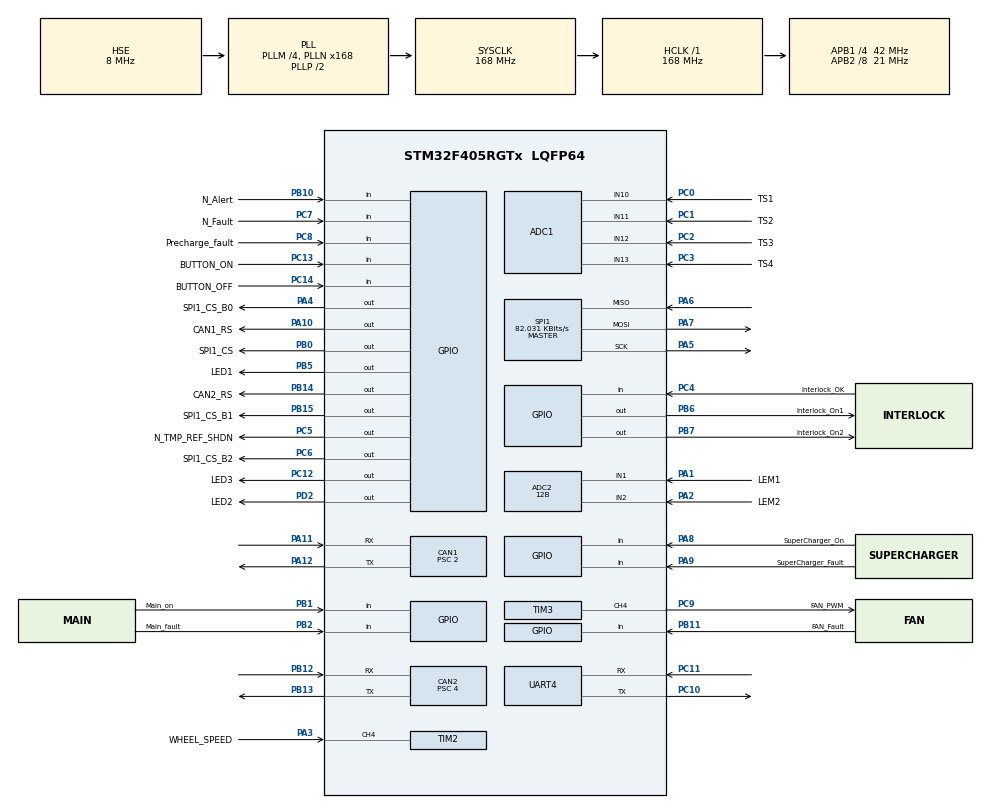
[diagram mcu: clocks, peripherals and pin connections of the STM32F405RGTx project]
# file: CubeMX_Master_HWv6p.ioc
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ADC1.Channel-15\#ChannelRegularConversion=ADC_CHANNEL_10
ADC1.Channel-16\#ChannelRegularConversion=ADC_CHANNEL_11
ADC1.Channel-17\#ChannelRegularConversion=ADC_CHANNEL_12
ADC1.Channel-18\#ChannelRegularConversion=ADC_CHANNEL_13
ADC1.ClockPrescaler=ADC_CLOCK_SYNC_PCLK_DIV2
ADC1.DMAContinuousRequests=ENABLE
ADC1.EOCSelection=ADC_EOC_SEQ_CONV
ADC1.NbrOfConversion=4
ADC1.NbrOfConversionFlag=1
ADC1.Rank-15\#ChannelRegularConversion=1
ADC1.Rank-16\#ChannelRegularConversion=2
ADC1.Rank-17\#ChannelRegularConversion=3
ADC1.Rank-18\#ChannelRegularConversion=4
ADC1.SamplingTime-15\#ChannelRegularConversion=ADC_SAMPLETIME_28CYCLES
ADC1.SamplingTime-16\#ChannelRegularConversion=ADC_SAMPLETIME_28CYCLES
ADC1.SamplingTime-17\#ChannelRegularConversion=ADC_SAMPLETIME_28CYCLES
ADC1.SamplingTime-18\#ChannelRegularConversion=ADC_SAMPLETIME_28CYCLES
ADC1.ScanConvMode=ENABLE
ADC1.master=1
ADC2.Channel-0\#ChannelRegularConversion=ADC_CHANNEL_1
ADC2.Channel-1\#ChannelRegularConversion=ADC_CHANNEL_2
ADC2.ClockPrescaler=ADC_CLOCK_SYNC_PCLK_DIV2
ADC2.ContinuousConvMode=DISABLE
ADC2.DMAContinuousRequests=ENABLE
ADC2.DataAlign=ADC_DATAALIGN_RIGHT
ADC2.DiscontinuousConvMode=DISABLE
ADC2.EOCSelection=ADC_EOC_SEQ_CONV
ADC2.EnableAnalogWatchDog=false
ADC2.ExternalTrigConv=ADC_SOFTWARE_START
ADC2.ExternalTrigConvEdge=ADC_EXTERNALTRIGCONVEDGE_NONE
ADC2.InjNumberOfConversion=0
ADC2.NbrOfConversion=2
ADC2.NbrOfConversionFlag=1
ADC2.Rank-0\#ChannelRegularConversion=1
ADC2.Rank-1\#ChannelRegularConversion=2
ADC2.Resolution=ADC_RESOLUTION_12B
ADC2.SamplingTime-0\#ChannelRegularConversion=ADC_SAMPLETIME_28CYCLES
ADC2.SamplingTime-1\#ChannelRegularConversion=ADC_SAMPLETIME_28CYCLES
ADC2.ScanConvMode=ENABLE
CAN1.BS1=CAN_BS1_12TQ
CAN1.BS2=CAN_BS2_8TQ
CAN1.CalculateTimeBit=1000
CAN1.CalculateTimeQuantum=47.61904761904762
CAN1.Prescaler=2
CAN2.BS1=CAN_BS1_12TQ
CAN2.BS2=CAN_BS2_8TQ
CAN2.CalculateTimeBit=2000
CAN2.CalculateTimeQuantum=95.23809523809524
CAN2.Prescaler=4
Dma.ADC1.1.Direction=DMA_PERIPH_TO_MEMORY
Dma.ADC1.1.FIFOMode=DMA_FIFOMODE_DISABLE
Dma.ADC1.1.Instance=DMA2_Stream0
Dma.ADC1.1.MemDataAlignment=DMA_MDATAALIGN_HALFWORD
Dma.ADC1.1.MemInc=DMA_MINC_ENABLE
Dma.ADC1.1.Mode=DMA_CIRCULAR
Dma.ADC1.1.PeriphDataAlignment=DMA_PDATAALIGN_HALFWORD
Dma.ADC1.1.PeriphInc=DMA_PINC_DISABLE
Dma.ADC1.1.Priority=DMA_PRIORITY_LOW
Dma.ADC2.0.Direction=DMA_PERIPH_TO_MEMORY
Dma.ADC2.0.FIFOMode=DMA_FIFOMODE_DISABLE
Dma.ADC2.0.Instance=DMA2_Stream2
Dma.ADC2.0.MemDataAlignment=DMA_MDATAALIGN_HALFWORD
Dma.ADC2.0.MemInc=DMA_MINC_ENABLE
Dma.ADC2.0.Mode=DMA_CIRCULAR
Dma.ADC2.0.PeriphDataAlignment=DMA_PDATAALIGN_HALFWORD
Dma.ADC2.0.PeriphInc=DMA_PINC_DISABLE
Dma.ADC2.0.Priority=DMA_PRIORITY_LOW
Dma.Request0=ADC2
Dma.Request1=ADC1
Mcu.Family=STM32F4
Mcu.Name=STM32F405RGTx
Mcu.Package=LQFP64
Mcu.UserConstants=BMS_MASTER_VERSION,6;TIM_6_FREQUENCY,4000;TIM_7_FREQUENCY,20;ADC1_NUM_CHANNELS,4;ADC2_NUM_CHANNELS,2;ADC_RANGE,4095
NVIC.CAN1_RX0_IRQn=true\:0\:0\:false\:false\:true
NVIC.CAN1_RX1_IRQn=true\:0\:0\:false\:false\:true
NVIC.CAN1_SCE_IRQn=true\:0\:0\:false\:false\:true
NVIC.CAN1_TX_IRQn=true\:0\:0\:false\:false\:true
NVIC.CAN2_RX0_IRQn=true\:0\:0\:false\:false\:true
NVIC.CAN2_RX1_IRQn=true\:0\:0\:false\:false\:true
NVIC.CAN2_SCE_IRQn=true\:0\:0\:false\:false\:true
NVIC.CAN2_TX_IRQn=true\:0\:0\:false\:false\:true
NVIC.DMA2_Stream0_IRQn=true\:0\:0\:false\:false\:true
NVIC.DMA2_Stream2_IRQn=true\:0\:0\:false\:false\:true
NVIC.PriorityGroup=NVIC_PRIORITYGROUP_4
NVIC.SPI1_IRQn=true\:0\:0\:false\:false\:true
NVIC.TIM2_IRQn=true\:0\:0\:false\:false\:true
NVIC.TIM3_IRQn=true\:0\:0\:false\:false\:true
NVIC.TIM6_DAC_IRQn=true\:0\:0\:false\:false\:true
NVIC.TIM7_IRQn=true\:0\:0\:false\:false\:true
PA1.GPIO_Label=LEM1
PA1.Signal=ADCx_IN1
PA10.GPIO_Label=CAN1_RS
PA10.Signal=GPIO_Output
PA11.Mode=Master
PA11.Signal=CAN1_RX
PA12.Mode=Master
PA12.Signal=CAN1_TX
PA13.Mode=JTAG_5_pins
PA13.Signal=SYS_JTMS-SWDIO
PA14.Mode=JTAG_5_pins
PA14.Signal=SYS_JTCK-SWCLK
PA15.Mode=JTAG_5_pins
PA15.Signal=SYS_JTDI
PA2.GPIO_Label=LEM2
PA2.Signal=ADCx_IN2
PA3.GPIO_Label=WHEEL_SPEED
PA3.Signal=S_TIM2_CH4
PA4.GPIO_Label=SPI1_CS_B0
PA4.GPIO_ModeDefaultOutputPP=GPIO_MODE_OUTPUT_OD
PA4.Signal=GPIO_Output
PA5.Mode=Full_Duplex_Master
PA5.Signal=SPI1_SCK
PA6.Mode=Full_Duplex_Master
PA6.Signal=SPI1_MISO
PA7.Mode=Full_Duplex_Master
PA7.Signal=SPI1_MOSI
PA8.GPIO_Label=SuperCharger_On
PA8.Signal=GPIO_Input
PA9.GPIO_Label=SuperCharger_Fault
PA9.Signal=GPIO_Input
PB0.GPIO_Label=SPI1_CS
PB0.GPIO_ModeDefaultOutputPP=GPIO_MODE_OUTPUT_OD
PB0.GPIO_Speed=GPIO_SPEED_FREQ_HIGH
PB0.Signal=GPIO_Output
PB1.GPIO_Label=Main_on
PB1.Signal=GPIO_Input
PB10.GPIO_Label=N_Alert
PB10.Signal=GPIO_Input
PB11.GPIO_Label=FAN_Fault
PB11.Signal=GPIO_Input
PB12.Mode=Slave
PB12.Signal=CAN2_RX
PB13.Mode=Slave
PB13.Signal=CAN2_TX
PB14.GPIO_Label=CAN2_RS
PB14.Signal=GPIO_Output
PB15.GPIO_Label=SPI1_CS_B1
PB15.GPIO_ModeDefaultOutputPP=GPIO_MODE_OUTPUT_OD
PB15.Signal=GPIO_Output
PB2.GPIO_Label=Main_fault
PB2.Signal=GPIO_Input
PB3.Mode=JTAG_5_pins
PB3.Signal=SYS_JTDO-SWO
PB4.Mode=JTAG_5_pins
PB4.Signal=SYS_JTRST
PB5.GPIO_Label=LED1
PB5.Signal=GPIO_Output
PB6.GPIO_Label=Interlock_On1
PB6.Signal=GPIO_Output
PB7.GPIO_Label=Interlock_On2
PB7.Signal=GPIO_Output
PC0.GPIO_Label=TS1
PC0.Signal=ADCx_IN10
PC1.GPIO_Label=TS2
PC1.Signal=ADCx_IN11
PC10.Mode=Asynchronous
PC10.Signal=UART4_TX
PC11.Mode=Asynchronous
PC11.Signal=UART4_RX
PC12.GPIO_Label=LED3
PC12.Signal=GPIO_Output
PC13-ANTI_TAMP.GPIO_Label=BUTTON_ON
PC13-ANTI_TAMP.GPIO_PuPd=GPIO_PULLDOWN
PC13-ANTI_TAMP.Signal=GPIO_Input
PC14-OSC32_IN.GPIO_Label=BUTTON_OFF
PC14-OSC32_IN.GPIO_PuPd=GPIO_PULLDOWN
PC14-OSC32_IN.Signal=GPIO_Input
PC2.GPIO_Label=TS3
PC2.Signal=ADCx_IN12
PC3.GPIO_Label=TS4
PC3.Signal=ADCx_IN13
PC4.GPIO_Label=Interlock_OK
PC4.GPIO_PuPd=GPIO_PULLDOWN
PC4.Signal=GPIO_Input
PC5.GPIO_Label=N_TMP_REF_SHDN
PC5.Signal=GPIO_Output
PC6.GPIO_Label=SPI1_CS_B2
PC6.GPIO_ModeDefaultOutputPP=GPIO_MODE_OUTPUT_OD
PC6.Signal=GPIO_Output
PC7.GPIO_Label=N_Fault
PC7.Signal=GPIO_Input
PC8.GPIO_Label=Precharge_fault
PC8.Signal=GPIO_Input
PC9.GPIO_Label=FAN_PWM
PC9.Signal=S_TIM3_CH4
PD2.GPIO_Label=LED2
PD2.Signal=GPIO_Output
PH0-OSC_IN.Mode=HSE-External-Oscillator
PH0-OSC_IN.Signal=RCC_OSC_IN
PH1-OSC_OUT.Mode=HSE-External-Oscillator
PH1-OSC_OUT.Signal=RCC_OSC_OUT
ProjectManager.HeapSize=0x200
ProjectManager.StackSize=0x400
ProjectManager.TargetToolchain=Other Toolchains (GPDSC)
RCC.48MHZClocksFreq_Value=84000000
RCC.AHBFreq_Value=168000000
RCC.APB1CLKDivider=RCC_HCLK_DIV4
RCC.APB1Freq_Value=42000000
RCC.APB1TimFreq_Value=84000000
RCC.APB2CLKDivider=RCC_HCLK_DIV8
RCC.APB2Freq_Value=21000000
RCC.APB2TimFreq_Value=42000000
RCC.CortexFreq_Value=168000000
RCC.HCLKFreq_Value=168000000
RCC.HSE_VALUE=8000000
RCC.HSI_VALUE=16000000
RCC.LSE_VALUE=32768
RCC.PLLM=4
RCC.PLLN=168
RCC.PLLSourceVirtual=RCC_PLLSOURCE_HSE
RCC.SYSCLKFreq_VALUE=168000000
RCC.SYSCLKSource=RCC_SYSCLKSOURCE_PLLCLK
RCC.VCOOutputFreq_Value=336000000
SH.ADCx_IN1.0=ADC2_IN1,IN1
SH.ADCx_IN10.0=ADC1_IN10,IN10
SH.ADCx_IN11.0=ADC1_IN11,IN11
SH.ADCx_IN12.0=ADC1_IN12,IN12
SH.ADCx_IN13.0=ADC1_IN13,IN13
SH.ADCx_IN2.0=ADC2_IN2,IN2
SH.S_TIM2_CH4.0=TIM2_CH4,Input_Capture4_from_TI4
SH.S_TIM3_CH4.0=TIM3_CH4,PWM Generation4 CH4
SPI1.BaudRatePrescaler=SPI_BAUDRATEPRESCALER_256
SPI1.CLKPhase=SPI_PHASE_2EDGE
SPI1.CRCCalculation=SPI_CRCCALCULATION_ENABLE
SPI1.CRCPolynomial=X2+X1+X0
SPI1.CalculateBaudRate=82.031 KBits/s
SPI1.Direction=SPI_DIRECTION_2LINES
SPI1.Mode=SPI_MODE_MASTER
SPI1.VirtualType=VM_MASTER
TIM2.Channel-Input_Capture4_from_TI4=TIM_CHANNEL_4
TIM2.ICFilter_CH4=7
TIM2.Period=3600000000
TIM2.Prescaler=839
TIM3.Channel-PWM\ Generation4\ CH4=TIM_CHANNEL_4
TIM6.Period=250
TIM6.Prescaler=83
TIM7.Period=500
TIM7.Prescaler=8399
UART4.VirtualMode=Asynchronous
VP_TIM3_VS_ClockSourceINT.Mode=Internal
VP_TIM6_VS_ClockSourceINT.Mode=Enable_Timer
VP_TIM7_VS_ClockSourceINT.Mode=Enable_Timer
board=CubeMX_Master_HWv6p

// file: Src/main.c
/**
  ******************************************************************************
  * File Name          : main.c
  * Description        : Main program body
  ******************************************************************************
  *
  * COPYRIGHT(c) 2017 STMicroelectronics
  *
  * Redistribution and use in source and binary forms, with or without modification,
  * are permitted provided that the following conditions are met:
  *   1. Redistributions of source code must retain the above copyright notice,
  *      this list of conditions and the following disclaimer.
  *   2. Redistributions in binary form must reproduce the above copyright notice,
  *      this list of conditions and the following disclaimer in the documentation
  *      and/or other materials provided with the distribution.
  *   3. Neither the name of STMicroelectronics nor the names of its contributors
  *      may be used to endorse or promote products derived from this software
  *      without specific prior written permission.
  *
  * THIS SOFTWARE IS PROVIDED BY THE COPYRIGHT HOLDERS AND CONTRIBUTORS "AS IS"
  * AND ANY EXPRESS OR IMPLIED WARRANTIES, INCLUDING, BUT NOT LIMITED TO, THE
  * IMPLIED WARRANTIES OF MERCHANTABILITY AND FITNESS FOR A PARTICULAR PURPOSE ARE
  * DISCLAIMED. IN NO EVENT SHALL THE COPYRIGHT HOLDER OR CONTRIBUTORS BE LIABLE
  * FOR ANY DIRECT, INDIRECT, INCIDENTAL, SPECIAL, EXEMPLARY, OR CONSEQUENTIAL
  * DAMAGES (INCLUDING, BUT NOT LIMITED TO, PROCUREMENT OF SUBSTITUTE GOODS OR
  * SERVICES; LOSS OF USE, DATA, OR PROFITS; OR BUSINESS INTERRUPTION) HOWEVER
  * CAUSED AND ON ANY THEORY OF LIABILITY, WHETHER IN CONTRACT, STRICT LIABILITY,
  * OR TORT (INCLUDING NEGLIGENCE OR OTHERWISE) ARISING IN ANY WAY OUT OF THE USE
  * OF THIS SOFTWARE, EVEN IF ADVISED OF THE POSSIBILITY OF SUCH DAMAGE.
  *
  ******************************************************************************
  */
#include "main.h"
#include "stm32f4xx_hal.h"

/* USER CODE BEGIN Includes */
#include "../../Src/core/userProgram.h"
/* USER CODE END Includes */

ADC_HandleTypeDef hadc1;
ADC_HandleTypeDef hadc2;
DMA_HandleTypeDef hdma_adc1;
DMA_HandleTypeDef hdma_adc2;

CAN_HandleTypeDef hcan1;
CAN_HandleTypeDef hcan2;

SPI_HandleTypeDef hspi1;

TIM_HandleTypeDef htim2;
TIM_HandleTypeDef htim3;
TIM_HandleTypeDef htim6;
TIM_HandleTypeDef htim7;

UART_HandleTypeDef huart4;

/* USER CODE BEGIN PV */
/* Private variables ---------------------------------------------------------*/

/* USER CODE END PV */

void SystemClock_Config(void);
void Error_Handler(void);
static void MX_GPIO_Init(void);
static void MX_DMA_Init(void);
static void MX_ADC2_Init(void);
static void MX_CAN1_Init(void);
static void MX_CAN2_Init(void);
static void MX_SPI1_Init(void);
static void MX_TIM3_Init(void);
static void MX_UART4_Init(void);
static void MX_TIM6_Init(void);
static void MX_TIM7_Init(void);
static void MX_ADC1_Init(void);
static void MX_TIM2_Init(void);

void HAL_TIM_MspPostInit(TIM_HandleTypeDef *htim);

/* USER CODE BEGIN PFP */
/* Private function prototypes -----------------------------------------------*/

/* USER CODE END PFP */

int main(void)
{

  /* MCU Configuration----------------------------------------------------------*/

  /* Reset of all peripherals, Initializes the Flash interface and the Systick. */
  HAL_Init();

  /* Configure the system clock */
  SystemClock_Config();

  /* Initialize all configured peripherals */
  MX_GPIO_Init();
  MX_DMA_Init();
  MX_ADC2_Init();
  MX_CAN1_Init();
  MX_CAN2_Init();
  MX_SPI1_Init();
  MX_TIM3_Init();
  MX_UART4_Init();
  MX_TIM6_Init();
  MX_TIM7_Init();
  MX_ADC1_Init();
  MX_TIM2_Init();

  /* USER CODE BEGIN 2 */
  userInit();
  /* USER CODE END 2 */

  /* Infinite loop */
  while (1)
  {

  /* USER CODE BEGIN 3 */
    userLoop();
  }
  /* USER CODE END 3 */

}

/** System Clock Configuration
*/
void SystemClock_Config(void)
{

  RCC_OscInitTypeDef RCC_OscInitStruct;
  RCC_ClkInitTypeDef RCC_ClkInitStruct;

    /**Configure the main internal regulator output voltage
    */
  __HAL_RCC_PWR_CLK_ENABLE();

  __HAL_PWR_VOLTAGESCALING_CONFIG(PWR_REGULATOR_VOLTAGE_SCALE1);

    /**Initializes the CPU, AHB and APB busses clocks
    */
  RCC_OscInitStruct.OscillatorType = RCC_OSCILLATORTYPE_HSE;
  RCC_OscInitStruct.HSEState = RCC_HSE_ON;
  RCC_OscInitStruct.PLL.PLLState = RCC_PLL_ON;
  RCC_OscInitStruct.PLL.PLLSource = RCC_PLLSOURCE_HSE;
  RCC_OscInitStruct.PLL.PLLM = 4;
  RCC_OscInitStruct.PLL.PLLN = 168;
  RCC_OscInitStruct.PLL.PLLP = RCC_PLLP_DIV2;
  RCC_OscInitStruct.PLL.PLLQ = 4;
  if (HAL_RCC_OscConfig(&RCC_OscInitStruct) != HAL_OK)
  {
    Error_Handler();
  }

    /**Initializes the CPU, AHB and APB busses clocks
    */
  RCC_ClkInitStruct.ClockType = RCC_CLOCKTYPE_HCLK|RCC_CLOCKTYPE_SYSCLK
                              |RCC_CLOCKTYPE_PCLK1|RCC_CLOCKTYPE_PCLK2;
  RCC_ClkInitStruct.SYSCLKSource = RCC_SYSCLKSOURCE_PLLCLK;
  RCC_ClkInitStruct.AHBCLKDivider = RCC_SYSCLK_DIV1;
  RCC_ClkInitStruct.APB1CLKDivider = RCC_HCLK_DIV4;
  RCC_ClkInitStruct.APB2CLKDivider = RCC_HCLK_DIV8;

  if (HAL_RCC_ClockConfig(&RCC_ClkInitStruct, FLASH_LATENCY_5) != HAL_OK)
  {
    Error_Handler();
  }

    /**Configure the Systick interrupt time
    */
  HAL_SYSTICK_Config(HAL_RCC_GetHCLKFreq()/1000);

    /**Configure the Systick
    */
  HAL_SYSTICK_CLKSourceConfig(SYSTICK_CLKSOURCE_HCLK);

  /* SysTick_IRQn interrupt configuration */
  HAL_NVIC_SetPriority(SysTick_IRQn, 0, 0);
}

/* ADC1 init function */
static void MX_ADC1_Init(void)
{

  ADC_ChannelConfTypeDef sConfig;

    /**Configure the global features of the ADC (Clock, Resolution, Data Alignment and number of conversion)
    */
  hadc1.Instance = ADC1;
  hadc1.Init.ClockPrescaler = ADC_CLOCK_SYNC_PCLK_DIV2;
  hadc1.Init.Resolution = ADC_RESOLUTION_12B;
  hadc1.Init.ScanConvMode = ENABLE;
  hadc1.Init.ContinuousConvMode = DISABLE;
  hadc1.Init.DiscontinuousConvMode = DISABLE;
  hadc1.Init.ExternalTrigConvEdge = ADC_EXTERNALTRIGCONVEDGE_NONE;
  hadc1.Init.ExternalTrigConv = ADC_SOFTWARE_START;
  hadc1.Init.DataAlign = ADC_DATAALIGN_RIGHT;
  hadc1.Init.NbrOfConversion = 4;
  hadc1.Init.DMAContinuousRequests = ENABLE;
  hadc1.Init.EOCSelection = ADC_EOC_SEQ_CONV;
  if (HAL_ADC_Init(&hadc1) != HAL_OK)
  {
    Error_Handler();
  }

    /**Configure for the selected ADC regular channel its corresponding rank in the sequencer and its sample time.
    */
  sConfig.Channel = ADC_CHANNEL_10;
  sConfig.Rank = 1;
  sConfig.SamplingTime = ADC_SAMPLETIME_28CYCLES;
  if (HAL_ADC_ConfigChannel(&hadc1, &sConfig) != HAL_OK)
  {
    Error_Handler();
  }

    /**Configure for the selected ADC regular channel its corresponding rank in the sequencer and its sample time.
    */
  sConfig.Channel = ADC_CHANNEL_11;
  sConfig.Rank = 2;
  if (HAL_ADC_ConfigChannel(&hadc1, &sConfig) != HAL_OK)
  {
    Error_Handler();
  }

    /**Configure for the selected ADC regular channel its corresponding rank in the sequencer and its sample time.
    */
  sConfig.Channel = ADC_CHANNEL_12;
  sConfig.Rank = 3;
  if (HAL_ADC_ConfigChannel(&hadc1, &sConfig) != HAL_OK)
  {
    Error_Handler();
  }

    /**Configure for the selected ADC regular channel its corresponding rank in the sequencer and its sample time.
    */
  sConfig.Channel = ADC_CHANNEL_13;
  sConfig.Rank = 4;
  if (HAL_ADC_ConfigChannel(&hadc1, &sConfig) != HAL_OK)
  {
    Error_Handler();
  }

}

/* ADC2 init function */
static void MX_ADC2_Init(void)
{

  ADC_ChannelConfTypeDef sConfig;

    /**Configure the global features of the ADC (Clock, Resolution, Data Alignment and number of conversion)
    */
  hadc2.Instance = ADC2;
  hadc2.Init.ClockPrescaler = ADC_CLOCK_SYNC_PCLK_DIV2;
  hadc2.Init.Resolution = ADC_RESOLUTION_12B;
  hadc2.Init.ScanConvMode = ENABLE;
  hadc2.Init.ContinuousConvMode = DISABLE;
  hadc2.Init.DiscontinuousConvMode = DISABLE;
  hadc2.Init.ExternalTrigConvEdge = ADC_EXTERNALTRIGCONVEDGE_NONE;
  hadc2.Init.ExternalTrigConv = ADC_SOFTWARE_START;
  hadc2.Init.DataAlign = ADC_DATAALIGN_RIGHT;
  hadc2.Init.NbrOfConversion = 2;
  hadc2.Init.DMAContinuousRequests = ENABLE;
  hadc2.Init.EOCSelection = ADC_EOC_SEQ_CONV;
  if (HAL_ADC_Init(&hadc2) != HAL_OK)
  {
    Error_Handler();
  }

    /**Configure for the selected ADC regular channel its corresponding rank in the sequencer and its sample time.
    */
  sConfig.Channel = ADC_CHANNEL_1;
  sConfig.Rank = 1;
  sConfig.SamplingTime = ADC_SAMPLETIME_28CYCLES;
  if (HAL_ADC_ConfigChannel(&hadc2, &sConfig) != HAL_OK)
  {
    Error_Handler();
  }

    /**Configure for the selected ADC regular channel its corresponding rank in the sequencer and its sample time.
    */
  sConfig.Channel = ADC_CHANNEL_2;
  sConfig.Rank = 2;
  if (HAL_ADC_ConfigChannel(&hadc2, &sConfig) != HAL_OK)
  {
    Error_Handler();
  }

}

/* CAN1 init function */
static void MX_CAN1_Init(void)
{

  hcan1.Instance = CAN1;
  hcan1.Init.Prescaler = 2;
  hcan1.Init.Mode = CAN_MODE_NORMAL;
  hcan1.Init.SJW = CAN_SJW_1TQ;
  hcan1.Init.BS1 = CAN_BS1_12TQ;
  hcan1.Init.BS2 = CAN_BS2_8TQ;
  hcan1.Init.TTCM = DISABLE;
  hcan1.Init.ABOM = DISABLE;
  hcan1.Init.AWUM = DISABLE;
  hcan1.Init.NART = DISABLE;
  hcan1.Init.RFLM = DISABLE;
  hcan1.Init.TXFP = DISABLE;
  if (HAL_CAN_Init(&hcan1) != HAL_OK)
  {
    Error_Handler();
  }

}

/* CAN2 init function */
static void MX_CAN2_Init(void)
{

  hcan2.Instance = CAN2;
  hcan2.Init.Prescaler = 4;
  hcan2.Init.Mode = CAN_MODE_NORMAL;
  hcan2.Init.SJW = CAN_SJW_1TQ;
  hcan2.Init.BS1 = CAN_BS1_12TQ;
  hcan2.Init.BS2 = CAN_BS2_8TQ;
  hcan2.Init.TTCM = DISABLE;
  hcan2.Init.ABOM = DISABLE;
  hcan2.Init.AWUM = DISABLE;
  hcan2.Init.NART = DISABLE;
  hcan2.Init.RFLM = DISABLE;
  hcan2.Init.TXFP = DISABLE;
  if (HAL_CAN_Init(&hcan2) != HAL_OK)
  {
    Error_Handler();
  }

}

/* SPI1 init function */
static void MX_SPI1_Init(void)
{

  hspi1.Instance = SPI1;
  hspi1.Init.Mode = SPI_MODE_MASTER;
  hspi1.Init.Direction = SPI_DIRECTION_2LINES;
  hspi1.Init.DataSize = SPI_DATASIZE_8BIT;
  hspi1.Init.CLKPolarity = SPI_POLARITY_LOW;
  hspi1.Init.CLKPhase = SPI_PHASE_2EDGE;
  hspi1.Init.NSS = SPI_NSS_SOFT;
  hspi1.Init.BaudRatePrescaler = SPI_BAUDRATEPRESCALER_256;
  hspi1.Init.FirstBit = SPI_FIRSTBIT_MSB;
  hspi1.Init.TIMode = SPI_TIMODE_DISABLE;
  hspi1.Init.CRCCalculation = SPI_CRCCALCULATION_ENABLE;
  hspi1.Init.CRCPolynomial = 7;
  if (HAL_SPI_Init(&hspi1) != HAL_OK)
  {
    Error_Handler();
  }

}

/* TIM2 init function */
static void MX_TIM2_Init(void)
{

  TIM_MasterConfigTypeDef sMasterConfig;
  TIM_IC_InitTypeDef sConfigIC;

  htim2.Instance = TIM2;
  htim2.Init.Prescaler = 839;
  htim2.Init.CounterMode = TIM_COUNTERMODE_UP;
  htim2.Init.Period = 3600000000;
  htim2.Init.ClockDivision = TIM_CLOCKDIVISION_DIV1;
  if (HAL_TIM_IC_Init(&htim2) != HAL_OK)
  {
    Error_Handler();
  }

  sMasterConfig.MasterOutputTrigger = TIM_TRGO_RESET;
  sMasterConfig.MasterSlaveMode = TIM_MASTERSLAVEMODE_DISABLE;
  if (HAL_TIMEx_MasterConfigSynchronization(&htim2, &sMasterConfig) != HAL_OK)
  {
    Error_Handler();
  }

  sConfigIC.ICPolarity = TIM_INPUTCHANNELPOLARITY_RISING;
  sConfigIC.ICSelection = TIM_ICSELECTION_DIRECTTI;
  sConfigIC.ICPrescaler = TIM_ICPSC_DIV1;
  sConfigIC.ICFilter = 7;
  if (HAL_TIM_IC_ConfigChannel(&htim2, &sConfigIC, TIM_CHANNEL_4) != HAL_OK)
  {
    Error_Handler();
  }

}

/* TIM3 init function */
static void MX_TIM3_Init(void)
{

  TIM_ClockConfigTypeDef sClockSourceConfig;
  TIM_MasterConfigTypeDef sMasterConfig;
  TIM_OC_InitTypeDef sConfigOC;

  htim3.Instance = TIM3;
  htim3.Init.Prescaler = 0;
  htim3.Init.CounterMode = TIM_COUNTERMODE_UP;
  htim3.Init.Period = 0;
  htim3.Init.ClockDivision = TIM_CLOCKDIVISION_DIV1;
  if (HAL_TIM_Base_Init(&htim3) != HAL_OK)
  {
    Error_Handler();
  }

  sClockSourceConfig.ClockSource = TIM_CLOCKSOURCE_INTERNAL;
  if (HAL_TIM_ConfigClockSource(&htim3, &sClockSourceConfig) != HAL_OK)
  {
    Error_Handler();
  }

  if (HAL_TIM_PWM_Init(&htim3) != HAL_OK)
  {
    Error_Handler();
  }

  sMasterConfig.MasterOutputTrigger = TIM_TRGO_RESET;
  sMasterConfig.MasterSlaveMode = TIM_MASTERSLAVEMODE_DISABLE;
  if (HAL_TIMEx_MasterConfigSynchronization(&htim3, &sMasterConfig) != HAL_OK)
  {
    Error_Handler();
  }

  sConfigOC.OCMode = TIM_OCMODE_PWM1;
  sConfigOC.Pulse = 0;
  sConfigOC.OCPolarity = TIM_OCPOLARITY_HIGH;
  sConfigOC.OCFastMode = TIM_OCFAST_DISABLE;
  if (HAL_TIM_PWM_ConfigChannel(&htim3, &sConfigOC, TIM_CHANNEL_4) != HAL_OK)
  {
    Error_Handler();
  }

  HAL_TIM_MspPostInit(&htim3);

}

/* TIM6 init function */
static void MX_TIM6_Init(void)
{

  TIM_MasterConfigTypeDef sMasterConfig;

  htim6.Instance = TIM6;
  htim6.Init.Prescaler = 83;
  htim6.Init.CounterMode = TIM_COUNTERMODE_UP;
  htim6.Init.Period = 250;
  if (HAL_TIM_Base_Init(&htim6) != HAL_OK)
  {
    Error_Handler();
  }

  sMasterConfig.MasterOutputTrigger = TIM_TRGO_RESET;
  sMasterConfig.MasterSlaveMode = TIM_MASTERSLAVEMODE_DISABLE;
  if (HAL_TIMEx_MasterConfigSynchronization(&htim6, &sMasterConfig) != HAL_OK)
  {
    Error_Handler();
  }

}

/* TIM7 init function */
static void MX_TIM7_Init(void)
{

  TIM_MasterConfigTypeDef sMasterConfig;

  htim7.Instance = TIM7;
  htim7.Init.Prescaler = 8399;
  htim7.Init.CounterMode = TIM_COUNTERMODE_UP;
  htim7.Init.Period = 500;
  if (HAL_TIM_Base_Init(&htim7) != HAL_OK)
  {
    Error_Handler();
  }

  sMasterConfig.MasterOutputTrigger = TIM_TRGO_RESET;
  sMasterConfig.MasterSlaveMode = TIM_MASTERSLAVEMODE_DISABLE;
  if (HAL_TIMEx_MasterConfigSynchronization(&htim7, &sMasterConfig) != HAL_OK)
  {
    Error_Handler();
  }

}

/* UART4 init function */
static void MX_UART4_Init(void)
{

  huart4.Instance = UART4;
  huart4.Init.BaudRate = 115200;
  huart4.Init.WordLength = UART_WORDLENGTH_8B;
  huart4.Init.StopBits = UART_STOPBITS_1;
  huart4.Init.Parity = UART_PARITY_NONE;
  huart4.Init.Mode = UART_MODE_TX_RX;
  huart4.Init.HwFlowCtl = UART_HWCONTROL_NONE;
  huart4.Init.OverSampling = UART_OVERSAMPLING_16;
  if (HAL_UART_Init(&huart4) != HAL_OK)
  {
    Error_Handler();
  }

}

static void MX_DMA_Init(void)
{
  /* DMA controller clock enable */
  __HAL_RCC_DMA2_CLK_ENABLE();

  /* DMA interrupt init */
  /* DMA2_Stream0_IRQn interrupt configuration */
  HAL_NVIC_SetPriority(DMA2_Stream0_IRQn, 0, 0);
  HAL_NVIC_EnableIRQ(DMA2_Stream0_IRQn);
  /* DMA2_Stream2_IRQn interrupt configuration */
  HAL_NVIC_SetPriority(DMA2_Stream2_IRQn, 0, 0);
  HAL_NVIC_EnableIRQ(DMA2_Stream2_IRQn);

}

/** Configure pins as
        * Analog
        * Input
        * Output
        * EVENT_OUT
        * EXTI
*/
static void MX_GPIO_Init(void)
{

  GPIO_InitTypeDef GPIO_InitStruct;

  /* GPIO Ports Clock Enable */
  __HAL_RCC_GPIOC_CLK_ENABLE();
  __HAL_RCC_GPIOH_CLK_ENABLE();
  __HAL_RCC_GPIOA_CLK_ENABLE();
  __HAL_RCC_GPIOB_CLK_ENABLE();
  __HAL_RCC_GPIOD_CLK_ENABLE();

  /*Configure GPIO pin Output Level */
  HAL_GPIO_WritePin(GPIOA, SPI1_CS_B0_Pin|CAN1_RS_Pin, GPIO_PIN_RESET);

  /*Configure GPIO pin Output Level */
  HAL_GPIO_WritePin(GPIOC, N_TMP_REF_SHDN_Pin|SPI1_CS_B2_Pin|LED3_Pin, GPIO_PIN_RESET);

  /*Configure GPIO pin Output Level */
  HAL_GPIO_WritePin(GPIOB, SPI1_CS_Pin|CAN2_RS_Pin|SPI1_CS_B1_Pin|LED1_Pin
                          |Interlock_On1_Pin|Interlock_On2_Pin, GPIO_PIN_RESET);

  /*Configure GPIO pin Output Level */
  HAL_GPIO_WritePin(LED2_GPIO_Port, LED2_Pin, GPIO_PIN_RESET);

  /*Configure GPIO pins : BUTTON_ON_Pin BUTTON_OFF_Pin Interlock_OK_Pin */
  GPIO_InitStruct.Pin = BUTTON_ON_Pin|BUTTON_OFF_Pin|Interlock_OK_Pin;
  GPIO_InitStruct.Mode = GPIO_MODE_INPUT;
  GPIO_InitStruct.Pull = GPIO_PULLDOWN;
  HAL_GPIO_Init(GPIOC, &GPIO_InitStruct);

  /*Configure GPIO pin : SPI1_CS_B0_Pin */
  GPIO_InitStruct.Pin = SPI1_CS_B0_Pin;
  GPIO_InitStruct.Mode = GPIO_MODE_OUTPUT_OD;
  GPIO_InitStruct.Pull = GPIO_NOPULL;
  GPIO_InitStruct.Speed = GPIO_SPEED_FREQ_LOW;
  HAL_GPIO_Init(SPI1_CS_B0_GPIO_Port, &GPIO_InitStruct);

  /*Configure GPIO pins : N_TMP_REF_SHDN_Pin LED3_Pin */
  GPIO_InitStruct.Pin = N_TMP_REF_SHDN_Pin|LED3_Pin;
  GPIO_InitStruct.Mode = GPIO_MODE_OUTPUT_PP;
  GPIO_InitStruct.Pull = GPIO_NOPULL;
  GPIO_InitStruct.Speed = GPIO_SPEED_FREQ_LOW;
  HAL_GPIO_Init(GPIOC, &GPIO_InitStruct);

  /*Configure GPIO pin : SPI1_CS_Pin */
  GPIO_InitStruct.Pin = SPI1_CS_Pin;
  GPIO_InitStruct.Mode = GPIO_MODE_OUTPUT_OD;
  GPIO_InitStruct.Pull = GPIO_NOPULL;
  GPIO_InitStruct.Speed = GPIO_SPEED_FREQ_HIGH;
  HAL_GPIO_Init(SPI1_CS_GPIO_Port, &GPIO_InitStruct);

  /*Configure GPIO pins : Main_on_Pin Main_fault_Pin N_Alert_Pin FAN_Fault_Pin */
  GPIO_InitStruct.Pin = Main_on_Pin|Main_fault_Pin|N_Alert_Pin|FAN_Fault_Pin;
  GPIO_InitStruct.Mode = GPIO_MODE_INPUT;
  GPIO_InitStruct.Pull = GPIO_NOPULL;
  HAL_GPIO_Init(GPIOB, &GPIO_InitStruct);

  /*Configure GPIO pins : CAN2_RS_Pin LED1_Pin Interlock_On1_Pin Interlock_On2_Pin */
  GPIO_InitStruct.Pin = CAN2_RS_Pin|LED1_Pin|Interlock_On1_Pin|Interlock_On2_Pin;
  GPIO_InitStruct.Mode = GPIO_MODE_OUTPUT_PP;
  GPIO_InitStruct.Pull = GPIO_NOPULL;
  GPIO_InitStruct.Speed = GPIO_SPEED_FREQ_LOW;
  HAL_GPIO_Init(GPIOB, &GPIO_InitStruct);

  /*Configure GPIO pin : SPI1_CS_B1_Pin */
  GPIO_InitStruct.Pin = SPI1_CS_B1_Pin;
  GPIO_InitStruct.Mode = GPIO_MODE_OUTPUT_OD;
  GPIO_InitStruct.Pull = GPIO_NOPULL;
  GPIO_InitStruct.Speed = GPIO_SPEED_FREQ_LOW;
  HAL_GPIO_Init(SPI1_CS_B1_GPIO_Port, &GPIO_InitStruct);

  /*Configure GPIO pin : SPI1_CS_B2_Pin */
  GPIO_InitStruct.Pin = SPI1_CS_B2_Pin;
  GPIO_InitStruct.Mode = GPIO_MODE_OUTPUT_OD;
  GPIO_InitStruct.Pull = GPIO_NOPULL;
  GPIO_InitStruct.Speed = GPIO_SPEED_FREQ_LOW;
  HAL_GPIO_Init(SPI1_CS_B2_GPIO_Port, &GPIO_InitStruct);

  /*Configure GPIO pins : N_Fault_Pin Precharge_fault_Pin */
  GPIO_InitStruct.Pin = N_Fault_Pin|Precharge_fault_Pin;
  GPIO_InitStruct.Mode = GPIO_MODE_INPUT;
  GPIO_InitStruct.Pull = GPIO_NOPULL;
  HAL_GPIO_Init(GPIOC, &GPIO_InitStruct);

  /*Configure GPIO pins : SuperCharger_On_Pin SuperCharger_Fault_Pin */
  GPIO_InitStruct.Pin = SuperCharger_On_Pin|SuperCharger_Fault_Pin;
  GPIO_InitStruct.Mode = GPIO_MODE_INPUT;
  GPIO_InitStruct.Pull = GPIO_NOPULL;
  HAL_GPIO_Init(GPIOA, &GPIO_InitStruct);

  /*Configure GPIO pin : CAN1_RS_Pin */
  GPIO_InitStruct.Pin = CAN1_RS_Pin;
  GPIO_InitStruct.Mode = GPIO_MODE_OUTPUT_PP;
  GPIO_InitStruct.Pull = GPIO_NOPULL;
  GPIO_InitStruct.Speed = GPIO_SPEED_FREQ_LOW;
  HAL_GPIO_Init(CAN1_RS_GPIO_Port, &GPIO_InitStruct);

  /*Configure GPIO pin : LED2_Pin */
  GPIO_InitStruct.Pin = LED2_Pin;
  GPIO_InitStruct.Mode = GPIO_MODE_OUTPUT_PP;
  GPIO_InitStruct.Pull = GPIO_NOPULL;
  GPIO_InitStruct.Speed = GPIO_SPEED_FREQ_LOW;
  HAL_GPIO_Init(LED2_GPIO_Port, &GPIO_InitStruct);

}

void Error_Handler(void)
{
  while(1)
  {
  }
}

/************************ (C) COPYRIGHT STMicroelectronics *****END OF FILE****/
